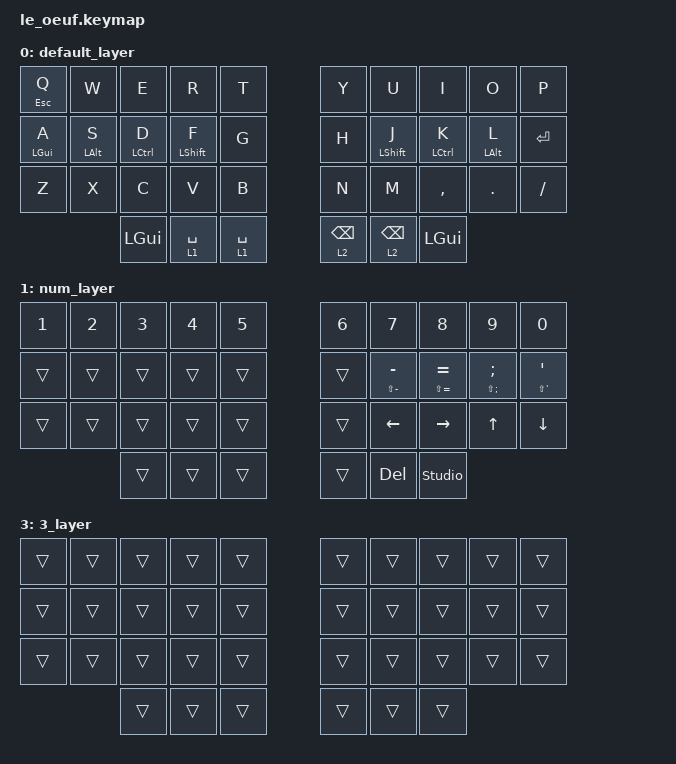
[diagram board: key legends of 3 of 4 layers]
#include <behaviors.dtsi>
#include <dt-bindings/zmk/keys.h>
#include <dt-bindings/zmk/bt.h>
#include <dt-bindings/zmk/outputs.h>

&mt {
    flavor = "balanced";
    tapping-term-ms = <200>;
};

&lt {
    flavor = "balanced";
    tapping-term-ms = <200>;
};

/ {
    keymap {
        compatible = "zmk,keymap";

        default_layer {
            bindings = <
                      &mt ESC Q      &kp W        &kp E         &kp R         &kp T                       &kp Y           &kp U         &kp I         &kp O          &kp P   
                      &mt LGUI A     &mt LALT S   &mt LCTRL D   &mt LSHIFT F  &kp G                       &kp H           &mt LSHIFT J  &mt LCTRL K   &mt LALT L     &kp ENTER
                      &kp Z          &kp X        &kp C         &kp V         &kp B                       &kp N           &kp M         &kp COMMA     &kp DOT        &kp FSLH
                                                  &kp LGUI      &lt 1 SPACE   &lt 1 SPACE                 &lt 2 BSPC      &lt 2 BSPC    &kp LGUI
            >;
        };

        num_layer {
            bindings = <
                      &kp N1         &kp N2       &kp N3        &kp N4        &kp N5                      &kp N6       &kp N7              &kp N8              &kp N9            &kp N0   
                      &trans         &trans       &trans        &trans        &trans                      &trans       &mt LS(MINUS) MINUS &mt LS(EQUAL) EQUAL &mt LS(SEMI) SEMI &mt LS(APOS) APOS
                      &trans         &trans       &trans        &trans        &trans                      &trans       &kp LEFT            &kp RIGHT           &kp UP            &kp DOWN
                                                  &trans        &trans        &trans                      &trans       &kp DEL             &studio_unlock
            >;
        };

        sym_layer {
            bindings = <
                      &bt BT_CLR     &bt BT_CLR     &bt BT_CLR     &bt BT_CLR     &trans                      &trans       &trans       &trans      &mt LS(LBKT)  LBKT &mt LS(RBKT) RBKT
                      &bt BT_DISC 0  &bt BT_DISC 1  &bt BT_DISC 2  &bt BT_DISC 3  &trans                      &trans       &trans       &trans      &trans        &trans
                      &bt BT_SEL 0   &bt BT_SEL 1   &bt BT_SEL 2   &bt BT_SEL 3   &trans                      &trans       &trans       &trans      &trans        &trans
                      &trans         &trans         &trans         &trans         &trans                      &trans       &trans       &trans      &trans        &trans
                                                    &trans         &trans         &trans                      &trans       &trans       &trans
            >;
        };

        3_layer {
            bindings = <
                      &trans         &trans       &trans       &trans       &trans                      &trans       &trans       &trans      &trans        &trans
                      &trans         &trans       &trans       &trans       &trans                      &trans       &trans       &trans      &trans        &trans
                      &trans         &trans       &trans       &trans       &trans                      &trans       &trans       &trans      &trans        &trans
                                                  &trans       &trans       &trans                      &trans       &trans       &trans
            >;
        };

    };
};


/ {
    combos {
        compatible = "zmk,combos";

        combo_esc {
            timeout-ms = <500>;
            key-positions = <0 1>;
            bindings = <&kp ESC>;
        };

        combo_tab {
            timeout-ms = <500>;
            key-positions = <10 11>;
            bindings = <&kp TAB>;
        };

        combo_backspace {
            timeout-ms = <500>;
            key-positions = <8 9>;
            bindings = <&kp BSPC>;
        };
    };
};
